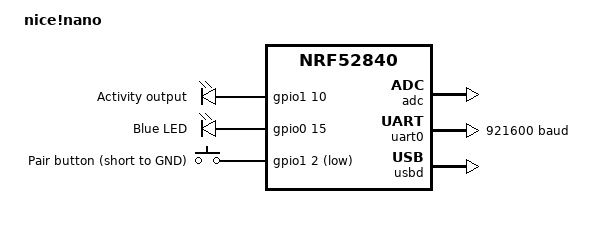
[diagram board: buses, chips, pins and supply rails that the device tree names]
/*
 * Copyright (c) 2020 Tobias Svehagen
 *
 * SPDX-License-Identifier: Apache-2.0
 */

/dts-v1/;
#include <nordic/nrf52840_qiaa.dtsi>
#include "nice_nano-pinctrl.dtsi"

/ {
	model = "nice!nano";
	compatible = "nice,nano";

	chosen {
		zephyr,console = &uart0;
		zephyr,shell-uart = &uart0;
		zephyr,uart-mcumgr = &uart0;
		zephyr,bt-mon-uart = &uart0;
		zephyr,bt-c2h-uart = &uart0;
		zephyr,sram = &sram0;
		zephyr,flash = &flash0;
		zephyr,code-partition = &code_partition;
	};

	leds {
		compatible = "gpio-leds";
		/* The board has one user LED, so the activity output stays on the
		 * same spare pin the Feather build uses. */
		led0: led_0 {
			gpios = <&gpio1 10 GPIO_ACTIVE_HIGH>;
			label = "Activity output";
		};
		led1: led_1 {
			gpios = <&gpio0 15 GPIO_ACTIVE_HIGH>;
			label = "Blue LED";
		};
	};

	buttons {
		compatible = "gpio-keys";
		button0: button_0 {
			gpios = <&gpio1 2 (GPIO_PULL_UP | GPIO_ACTIVE_LOW)>;
			label = "Pair button (short to GND)";
		};
	};

	aliases {
		led0 = &led0;
		led1 = &led1;
		sw0 = &button0;
	};
};

&adc {
	status = "okay";
};

&gpiote {
	status = "okay";
};

&gpio0 {
	status = "okay";
};

&gpio1 {
	status = "okay";
};

&uart0 {
	compatible = "nordic,nrf-uart";
	current-speed = <921600>;
	status = "okay";
	pinctrl-0 = <&uart0_default>;
	pinctrl-1 = <&uart0_sleep>;
	pinctrl-names = "default", "sleep";
};

&flash0 {

	partitions {
		compatible = "fixed-partitions";
		#address-cells = <1>;
		#size-cells = <1>;

		sd_partition: partition@0 {
			label = "softdevice";
			reg = <0x00000000 0x00026000>;
		};

		code_partition: partition@26000 {
			label = "code_partition";
			reg = <0x00026000 0x000c6000>;
		};

		storage_partition: partition@ec000 {
			label = "storage";
			reg = <0x000ec000 0x00008000>;
		};

		boot_partition: partition@f4000 {
			label = "adafruit_boot";
			reg = <0x000f4000 0x0000c000>;
		};
	};
};

zephyr_udc0: &usbd {
	compatible = "nordic,nrf-usbd";
	status = "okay";
};
